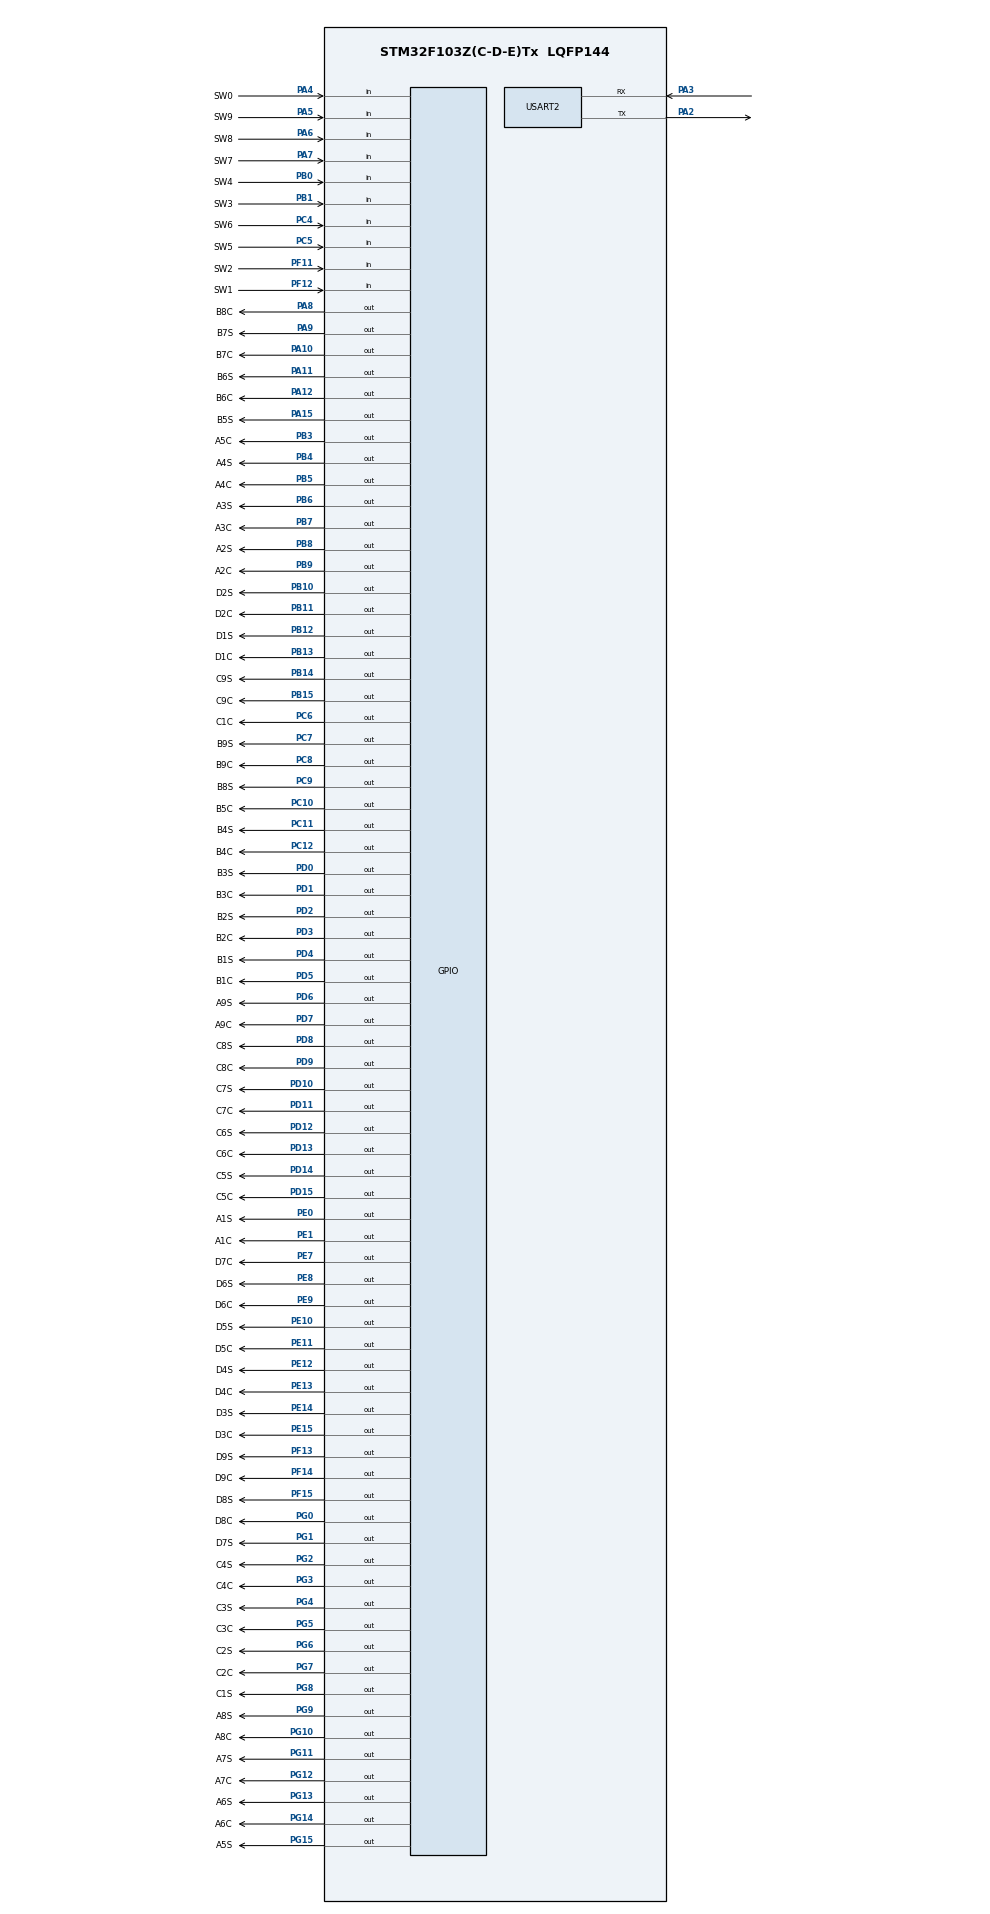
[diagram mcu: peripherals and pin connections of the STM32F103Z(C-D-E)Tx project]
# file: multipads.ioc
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Dma.Request0=USART2_RX
Dma.USART2_RX.0.Direction=DMA_PERIPH_TO_MEMORY
Dma.USART2_RX.0.Instance=DMA1_Channel6
Dma.USART2_RX.0.MemDataAlignment=DMA_MDATAALIGN_BYTE
Dma.USART2_RX.0.MemInc=DMA_MINC_ENABLE
Dma.USART2_RX.0.Mode=DMA_NORMAL
Dma.USART2_RX.0.PeriphDataAlignment=DMA_PDATAALIGN_BYTE
Dma.USART2_RX.0.PeriphInc=DMA_PINC_DISABLE
Dma.USART2_RX.0.Priority=DMA_PRIORITY_LOW
FREERTOS.Queues01=requestQueue,1,profile_t,0,Dynamic,NULL,NULL
FREERTOS.Tasks01=uxTask,0,1024,StartUxTask,As weak,NULL,Dynamic,NULL,NULL;profileTask,1,1024,StartProfileTask,As external,NULL,Dynamic,NULL,NULL
FREERTOS.configTOTAL_HEAP_SIZE=16384
FREERTOS.configUSE_NEWLIB_REENTRANT=1
Mcu.Family=STM32F1
Mcu.Name=STM32F103Z(C-D-E)Tx
Mcu.Package=LQFP144
NVIC.DMA1_Channel6_IRQn=true\:5\:0\:false\:false\:true\:true\:false\:true\:true
NVIC.PriorityGroup=NVIC_PRIORITYGROUP_4
NVIC.TIM1_UP_IRQn=true\:15\:0\:false\:false\:true\:false\:false\:true\:true
NVIC.TimeBase=TIM1_UP_IRQn
NVIC.TimeBaseIP=TIM1
OSC_IN.Mode=HSE-External-Oscillator
OSC_IN.Signal=RCC_OSC_IN
OSC_OUT.Mode=HSE-External-Oscillator
OSC_OUT.Signal=RCC_OSC_OUT
PA10.GPIO_Label=B7C
PA10.Signal=GPIO_Output
PA11.GPIO_Label=B6S
PA11.Signal=GPIO_Output
PA12.GPIO_Label=B6C
PA12.Signal=GPIO_Output
PA13.Mode=Serial_Wire
PA13.Signal=SYS_JTMS-SWDIO
PA14.Mode=Serial_Wire
PA14.Signal=SYS_JTCK-SWCLK
PA15.GPIO_Label=B5S
PA15.Signal=GPIO_Output
PA2.Mode=Asynchronous
PA2.Signal=USART2_TX
PA3.Mode=Asynchronous
PA3.Signal=USART2_RX
PA4.GPIO_Label=SW0
PA4.Signal=GPIO_Input
PA5.GPIO_Label=SW9
PA5.Signal=GPIO_Input
PA6.GPIO_Label=SW8
PA6.Signal=GPIO_Input
PA7.GPIO_Label=SW7
PA7.Signal=GPIO_Input
PA8.GPIO_Label=B8C
PA8.Signal=GPIO_Output
PA9.GPIO_Label=B7S
PA9.Signal=GPIO_Output
PB0.GPIO_Label=SW4
PB0.Signal=GPIO_Input
PB1.GPIO_Label=SW3
PB1.Signal=GPIO_Input
PB10.GPIO_Label=D2S
PB10.Signal=GPIO_Output
PB11.GPIO_Label=D2C
PB11.Signal=GPIO_Output
PB12.GPIO_Label=D1S
PB12.Signal=GPIO_Output
PB13.GPIO_Label=D1C
PB13.Signal=GPIO_Output
PB14.GPIO_Label=C9S
PB14.Signal=GPIO_Output
PB15.GPIO_Label=C9C
PB15.Signal=GPIO_Output
PB3.GPIO_Label=A5C
PB3.Signal=GPIO_Output
PB4.GPIO_Label=A4S
PB4.Signal=GPIO_Output
PB5.GPIO_Label=A4C
PB5.Signal=GPIO_Output
PB6.GPIO_Label=A3S
PB6.Signal=GPIO_Output
PB7.GPIO_Label=A3C
PB7.Signal=GPIO_Output
PB8.GPIO_Label=A2S
PB8.Signal=GPIO_Output
PB9.GPIO_Label=A2C
PB9.Signal=GPIO_Output
PC10.GPIO_Label=B5C
PC10.Signal=GPIO_Output
PC11.GPIO_Label=B4S
PC11.Signal=GPIO_Output
PC12.GPIO_Label=B4C
PC12.Signal=GPIO_Output
PC4.GPIO_Label=SW6
PC4.Signal=GPIO_Input
PC5.GPIO_Label=SW5
PC5.Signal=GPIO_Input
PC6.GPIO_Label=C1C
PC6.Signal=GPIO_Output
PC7.GPIO_Label=B9S
PC7.Signal=GPIO_Output
PC8.GPIO_Label=B9C
PC8.Signal=GPIO_Output
PC9.GPIO_Label=B8S
PC9.Signal=GPIO_Output
PD0.GPIO_Label=B3S
PD0.Signal=GPIO_Output
PD1.GPIO_Label=B3C
PD1.Signal=GPIO_Output
PD10.GPIO_Label=C7S
PD10.Signal=GPIO_Output
PD11.GPIO_Label=C7C
PD11.Signal=GPIO_Output
PD12.GPIO_Label=C6S
PD12.Signal=GPIO_Output
PD13.GPIO_Label=C6C
PD13.Signal=GPIO_Output
PD14.GPIO_Label=C5S
PD14.Signal=GPIO_Output
PD15.GPIO_Label=C5C
PD15.Signal=GPIO_Output
PD2.GPIO_Label=B2S
PD2.Signal=GPIO_Output
PD3.GPIO_Label=B2C
PD3.Signal=GPIO_Output
PD4.GPIO_Label=B1S
PD4.Signal=GPIO_Output
PD5.GPIO_Label=B1C
PD5.Signal=GPIO_Output
PD6.GPIO_Label=A9S
PD6.Signal=GPIO_Output
PD7.GPIO_Label=A9C
PD7.Signal=GPIO_Output
PD8.GPIO_Label=C8S
PD8.Signal=GPIO_Output
PD9.GPIO_Label=C8C
PD9.Signal=GPIO_Output
PE0.GPIO_Label=A1S
PE0.Signal=GPIO_Output
PE1.GPIO_Label=A1C
PE1.Signal=GPIO_Output
PE10.GPIO_Label=D5S
PE10.Signal=GPIO_Output
PE11.GPIO_Label=D5C
PE11.Signal=GPIO_Output
PE12.GPIO_Label=D4S
PE12.Signal=GPIO_Output
PE13.GPIO_Label=D4C
PE13.Signal=GPIO_Output
PE14.GPIO_Label=D3S
PE14.Signal=GPIO_Output
PE15.GPIO_Label=D3C
PE15.Signal=GPIO_Output
PE7.GPIO_Label=D7C
PE7.Signal=GPIO_Output
PE8.GPIO_Label=D6S
PE8.Signal=GPIO_Output
PE9.GPIO_Label=D6C
PE9.Signal=GPIO_Output
PF11.GPIO_Label=SW2
PF11.Signal=GPIO_Input
PF12.GPIO_Label=SW1
PF12.Signal=GPIO_Input
PF13.GPIO_Label=D9S
PF13.Signal=GPIO_Output
PF14.GPIO_Label=D9C
PF14.Signal=GPIO_Output
PF15.GPIO_Label=D8S
PF15.Signal=GPIO_Output
PG0.GPIO_Label=D8C
PG0.Signal=GPIO_Output
PG1.GPIO_Label=D7S
PG1.Signal=GPIO_Output
PG10.GPIO_Label=A8C
PG10.Signal=GPIO_Output
PG11.GPIO_Label=A7S
PG11.Signal=GPIO_Output
PG12.GPIO_Label=A7C
PG12.Signal=GPIO_Output
PG13.GPIO_Label=A6S
PG13.Signal=GPIO_Output
PG14.GPIO_Label=A6C
PG14.Signal=GPIO_Output
PG15.GPIO_Label=A5S
PG15.Signal=GPIO_Output
PG2.GPIO_Label=C4S
PG2.Signal=GPIO_Output
PG3.GPIO_Label=C4C
PG3.Signal=GPIO_Output
PG4.GPIO_Label=C3S
PG4.Signal=GPIO_Output
PG5.GPIO_Label=C3C
PG5.Signal=GPIO_Output
PG6.GPIO_Label=C2S
PG6.Signal=GPIO_Output
PG7.GPIO_Label=C2C
PG7.Signal=GPIO_Output
PG8.GPIO_Label=C1S
PG8.Signal=GPIO_Output
PG9.GPIO_Label=A8S
PG9.Signal=GPIO_Output
ProjectManager.HeapSize=0x200
ProjectManager.StackSize=0x400
ProjectManager.TargetToolchain=STM32CubeIDE
RCC.APB1Freq_Value=8000000
RCC.APB2Freq_Value=8000000
USART2.VirtualMode=VM_ASYNC
VP_CRC_VS_CRC.Mode=CRC_Activate
VP_FREERTOS_VS_CMSIS_V1.Mode=CMSIS_V1
VP_SYS_VS_tim1.Mode=TIM1
board=custom

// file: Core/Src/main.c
/* USER CODE BEGIN Header */
/**
  ******************************************************************************
  * @file           : main.c
  * @brief          : Main program body
  ******************************************************************************
  * @attention
  *
  * Copyright (c) 2023 STMicroelectronics.
  * All rights reserved.
  *
  * This software is licensed under terms that can be found in the LICENSE file
  * in the root directory of this software component.
  * If no LICENSE file comes with this software, it is provided AS-IS.
  *
  ******************************************************************************
  */

#include <string.h>
/* USER CODE END Header */
#include "main.h"
#include "cmsis_os.h"

/* USER CODE BEGIN Includes */
#include "command.h"
#include "profile.h"
/* USER CODE END Includes */

/* USER CODE BEGIN PTD */
typedef enum
{
	BTN_RELEASED = 0,
	BTN_DEBOUNCING,
	BTN_PRESSED,	// waiting for release
} BTN_StatusTypeDef;
/* USER CODE END PTD */

CRC_HandleTypeDef hcrc;

UART_HandleTypeDef huart2;
DMA_HandleTypeDef hdma_usart2_rx;

osThreadId uxTaskHandle;
osThreadId profileTaskHandle;
osMessageQId requestQueueHandle;
/* USER CODE BEGIN PV */

static BTN_StatusTypeDef btn_status = BTN_PRESSED;
int btn_index = -1;
int btn_count = 0;

/* USER CODE END PV */

void SystemClock_Config(void);
static void MX_GPIO_Init(void);
static void MX_DMA_Init(void);
static void MX_USART2_UART_Init(void);
static void MX_CRC_Init(void);
void StartUxTask(void const * argument);
extern void StartProfileTask(void const * argument);

/* USER CODE BEGIN 0 */
/*
 * Write char to uart in blocking mode
 */

// TODO remove this function
static void UART2_write(const char * str)
{
	int len = strlen(str);
	if (len == 0)
	{
		return;
	}

	HAL_UART_Transmit(&huart2, (const uint8_t *)str, len, HAL_MAX_DELAY);
}

void print_line(const char *str)
{
	UART2_write(str);
	UART2_write("\r\n");
}

/* USER CODE END 0 */

int main(void)
{

  /* MCU Configuration--------------------------------------------------------*/

  /* Reset of all peripherals, Initializes the Flash interface and the Systick. */
  HAL_Init();

  /* Configure the system clock */
  SystemClock_Config();

  /* Initialize all configured peripherals */
  MX_GPIO_Init();
  MX_DMA_Init();
  MX_USART2_UART_Init();
  MX_CRC_Init();

  /* Create the queue(s) */
  /* definition and creation of requestQueue */
  osMessageQDef(requestQueue, 1, profile_t);
  requestQueueHandle = osMessageCreate(osMessageQ(requestQueue), NULL);

  /* Create the thread(s) */
  /* definition and creation of uxTask */
  osThreadDef(uxTask, StartUxTask, osPriorityNormal, 0, 1024);
  uxTaskHandle = osThreadCreate(osThread(uxTask), NULL);

  /* definition and creation of profileTask */
  osThreadDef(profileTask, StartProfileTask, osPriorityAboveNormal, 0, 1024);
  profileTaskHandle = osThreadCreate(osThread(profileTask), NULL);

  /* Start scheduler */
  osKernelStart();

  /* We should never get here as control is now taken by the scheduler */

  /* Infinite loop */
  while (1)
  {

  }
}

void SystemClock_Config(void)
{
  RCC_OscInitTypeDef RCC_OscInitStruct = {0};
  RCC_ClkInitTypeDef RCC_ClkInitStruct = {0};

  /** Initializes the RCC Oscillators according to the specified parameters
  * in the RCC_OscInitTypeDef structure.
  */
  RCC_OscInitStruct.OscillatorType = RCC_OSCILLATORTYPE_HSI;
  RCC_OscInitStruct.HSIState = RCC_HSI_ON;
  RCC_OscInitStruct.HSICalibrationValue = RCC_HSICALIBRATION_DEFAULT;
  RCC_OscInitStruct.PLL.PLLState = RCC_PLL_NONE;
  if (HAL_RCC_OscConfig(&RCC_OscInitStruct) != HAL_OK)
  {
    Error_Handler();
  }

  /** Initializes the CPU, AHB and APB buses clocks
  */
  RCC_ClkInitStruct.ClockType = RCC_CLOCKTYPE_HCLK|RCC_CLOCKTYPE_SYSCLK
                              |RCC_CLOCKTYPE_PCLK1|RCC_CLOCKTYPE_PCLK2;
  RCC_ClkInitStruct.SYSCLKSource = RCC_SYSCLKSOURCE_HSI;
  RCC_ClkInitStruct.AHBCLKDivider = RCC_SYSCLK_DIV1;
  RCC_ClkInitStruct.APB1CLKDivider = RCC_HCLK_DIV1;
  RCC_ClkInitStruct.APB2CLKDivider = RCC_HCLK_DIV1;

  if (HAL_RCC_ClockConfig(&RCC_ClkInitStruct, FLASH_LATENCY_0) != HAL_OK)
  {
    Error_Handler();
  }
}

static void MX_CRC_Init(void)
{

  hcrc.Instance = CRC;
  if (HAL_CRC_Init(&hcrc) != HAL_OK)
  {
    Error_Handler();
  }

}

static void MX_USART2_UART_Init(void)
{

  huart2.Instance = USART2;
  huart2.Init.BaudRate = 115200;
  huart2.Init.WordLength = UART_WORDLENGTH_8B;
  huart2.Init.StopBits = UART_STOPBITS_1;
  huart2.Init.Parity = UART_PARITY_NONE;
  huart2.Init.Mode = UART_MODE_TX_RX;
  huart2.Init.HwFlowCtl = UART_HWCONTROL_NONE;
  huart2.Init.OverSampling = UART_OVERSAMPLING_16;
  if (HAL_UART_Init(&huart2) != HAL_OK)
  {
    Error_Handler();
  }

}

static void MX_DMA_Init(void)
{

  /* DMA controller clock enable */
  __HAL_RCC_DMA1_CLK_ENABLE();

  /* DMA interrupt init */
  /* DMA1_Channel6_IRQn interrupt configuration */
  HAL_NVIC_SetPriority(DMA1_Channel6_IRQn, 5, 0);
  HAL_NVIC_EnableIRQ(DMA1_Channel6_IRQn);

}

static void MX_GPIO_Init(void)
{
  GPIO_InitTypeDef GPIO_InitStruct = {0};

  /* GPIO Ports Clock Enable */
  __HAL_RCC_GPIOA_CLK_ENABLE();
  __HAL_RCC_GPIOC_CLK_ENABLE();
  __HAL_RCC_GPIOB_CLK_ENABLE();
  __HAL_RCC_GPIOF_CLK_ENABLE();
  __HAL_RCC_GPIOG_CLK_ENABLE();
  __HAL_RCC_GPIOE_CLK_ENABLE();
  __HAL_RCC_GPIOD_CLK_ENABLE();

  /*Configure GPIO pin Output Level */
  HAL_GPIO_WritePin(GPIOF, D9S_Pin|D9C_Pin|D8S_Pin, GPIO_PIN_RESET);

  /*Configure GPIO pin Output Level */
  HAL_GPIO_WritePin(GPIOG, D8C_Pin|D7S_Pin|C4S_Pin|C4C_Pin
                          |C3S_Pin|C3C_Pin|C2S_Pin|C2C_Pin
                          |C1S_Pin|A8S_Pin|A8C_Pin|A7S_Pin
                          |A7C_Pin|A6S_Pin|A6C_Pin|A5S_Pin, GPIO_PIN_RESET);

  /*Configure GPIO pin Output Level */
  HAL_GPIO_WritePin(GPIOE, D7C_Pin|D6S_Pin|D6C_Pin|D5S_Pin
                          |D5C_Pin|D4S_Pin|D4C_Pin|D3S_Pin
                          |D3C_Pin|A1S_Pin|A1C_Pin, GPIO_PIN_RESET);

  /*Configure GPIO pin Output Level */
  HAL_GPIO_WritePin(GPIOB, D2S_Pin|D2C_Pin|D1S_Pin|D1C_Pin
                          |C9S_Pin|C9C_Pin|A5C_Pin|A4S_Pin
                          |A4C_Pin|A3S_Pin|A3C_Pin|A2S_Pin
                          |A2C_Pin, GPIO_PIN_RESET);

  /*Configure GPIO pin Output Level */
  HAL_GPIO_WritePin(GPIOD, C8S_Pin|C8C_Pin|C7S_Pin|C7C_Pin
                          |C6S_Pin|C6C_Pin|C5S_Pin|C5C_Pin
                          |B3S_Pin|B3C_Pin|B2S_Pin|B2C_Pin
                          |B1S_Pin|B1C_Pin|A9S_Pin|A9C_Pin, GPIO_PIN_RESET);

  /*Configure GPIO pin Output Level */
  HAL_GPIO_WritePin(GPIOC, C1C_Pin|B9S_Pin|B9C_Pin|B8S_Pin
                          |B5C_Pin|B4S_Pin|B4C_Pin, GPIO_PIN_RESET);

  /*Configure GPIO pin Output Level */
  HAL_GPIO_WritePin(GPIOA, B8C_Pin|B7S_Pin|B7C_Pin|B6S_Pin
                          |B6C_Pin|B5S_Pin, GPIO_PIN_RESET);

  /*Configure GPIO pins : SW0_Pin SW9_Pin SW8_Pin SW7_Pin */
  GPIO_InitStruct.Pin = SW0_Pin|SW9_Pin|SW8_Pin|SW7_Pin;
  GPIO_InitStruct.Mode = GPIO_MODE_INPUT;
  GPIO_InitStruct.Pull = GPIO_NOPULL;
  HAL_GPIO_Init(GPIOA, &GPIO_InitStruct);

  /*Configure GPIO pins : SW6_Pin SW5_Pin */
  GPIO_InitStruct.Pin = SW6_Pin|SW5_Pin;
  GPIO_InitStruct.Mode = GPIO_MODE_INPUT;
  GPIO_InitStruct.Pull = GPIO_NOPULL;
  HAL_GPIO_Init(GPIOC, &GPIO_InitStruct);

  /*Configure GPIO pins : SW4_Pin SW3_Pin */
  GPIO_InitStruct.Pin = SW4_Pin|SW3_Pin;
  GPIO_InitStruct.Mode = GPIO_MODE_INPUT;
  GPIO_InitStruct.Pull = GPIO_NOPULL;
  HAL_GPIO_Init(GPIOB, &GPIO_InitStruct);

  /*Configure GPIO pins : SW2_Pin SW1_Pin */
  GPIO_InitStruct.Pin = SW2_Pin|SW1_Pin;
  GPIO_InitStruct.Mode = GPIO_MODE_INPUT;
  GPIO_InitStruct.Pull = GPIO_NOPULL;
  HAL_GPIO_Init(GPIOF, &GPIO_InitStruct);

  /*Configure GPIO pins : D9S_Pin D9C_Pin D8S_Pin */
  GPIO_InitStruct.Pin = D9S_Pin|D9C_Pin|D8S_Pin;
  GPIO_InitStruct.Mode = GPIO_MODE_OUTPUT_PP;
  GPIO_InitStruct.Pull = GPIO_NOPULL;
  GPIO_InitStruct.Speed = GPIO_SPEED_FREQ_LOW;
  HAL_GPIO_Init(GPIOF, &GPIO_InitStruct);

  /*Configure GPIO pins : D8C_Pin D7S_Pin C4S_Pin C4C_Pin
                           C3S_Pin C3C_Pin C2S_Pin C2C_Pin
                           C1S_Pin A8S_Pin A8C_Pin A7S_Pin
                           A7C_Pin A6S_Pin A6C_Pin A5S_Pin */
  GPIO_InitStruct.Pin = D8C_Pin|D7S_Pin|C4S_Pin|C4C_Pin
                          |C3S_Pin|C3C_Pin|C2S_Pin|C2C_Pin
                          |C1S_Pin|A8S_Pin|A8C_Pin|A7S_Pin
                          |A7C_Pin|A6S_Pin|A6C_Pin|A5S_Pin;
  GPIO_InitStruct.Mode = GPIO_MODE_OUTPUT_PP;
  GPIO_InitStruct.Pull = GPIO_NOPULL;
  GPIO_InitStruct.Speed = GPIO_SPEED_FREQ_LOW;
  HAL_GPIO_Init(GPIOG, &GPIO_InitStruct);

  /*Configure GPIO pins : D7C_Pin D6S_Pin D6C_Pin D5S_Pin
                           D5C_Pin D4S_Pin D4C_Pin D3S_Pin
                           D3C_Pin A1S_Pin A1C_Pin */
  GPIO_InitStruct.Pin = D7C_Pin|D6S_Pin|D6C_Pin|D5S_Pin
                          |D5C_Pin|D4S_Pin|D4C_Pin|D3S_Pin
                          |D3C_Pin|A1S_Pin|A1C_Pin;
  GPIO_InitStruct.Mode = GPIO_MODE_OUTPUT_PP;
  GPIO_InitStruct.Pull = GPIO_NOPULL;
  GPIO_InitStruct.Speed = GPIO_SPEED_FREQ_LOW;
  HAL_GPIO_Init(GPIOE, &GPIO_InitStruct);

  /*Configure GPIO pins : D2S_Pin D2C_Pin D1S_Pin D1C_Pin
                           C9S_Pin C9C_Pin A5C_Pin A4S_Pin
                           A4C_Pin A3S_Pin A3C_Pin A2S_Pin
                           A2C_Pin */
  GPIO_InitStruct.Pin = D2S_Pin|D2C_Pin|D1S_Pin|D1C_Pin
                          |C9S_Pin|C9C_Pin|A5C_Pin|A4S_Pin
                          |A4C_Pin|A3S_Pin|A3C_Pin|A2S_Pin
                          |A2C_Pin;
  GPIO_InitStruct.Mode = GPIO_MODE_OUTPUT_PP;
  GPIO_InitStruct.Pull = GPIO_NOPULL;
  GPIO_InitStruct.Speed = GPIO_SPEED_FREQ_LOW;
  HAL_GPIO_Init(GPIOB, &GPIO_InitStruct);

  /*Configure GPIO pins : C8S_Pin C8C_Pin C7S_Pin C7C_Pin
                           C6S_Pin C6C_Pin C5S_Pin C5C_Pin
                           B3S_Pin B3C_Pin B2S_Pin B2C_Pin
                           B1S_Pin B1C_Pin A9S_Pin A9C_Pin */
  GPIO_InitStruct.Pin = C8S_Pin|C8C_Pin|C7S_Pin|C7C_Pin
                          |C6S_Pin|C6C_Pin|C5S_Pin|C5C_Pin
                          |B3S_Pin|B3C_Pin|B2S_Pin|B2C_Pin
                          |B1S_Pin|B1C_Pin|A9S_Pin|A9C_Pin;
  GPIO_InitStruct.Mode = GPIO_MODE_OUTPUT_PP;
  GPIO_InitStruct.Pull = GPIO_NOPULL;
  GPIO_InitStruct.Speed = GPIO_SPEED_FREQ_LOW;
  HAL_GPIO_Init(GPIOD, &GPIO_InitStruct);

  /*Configure GPIO pins : C1C_Pin B9S_Pin B9C_Pin B8S_Pin
                           B5C_Pin B4S_Pin B4C_Pin */
  GPIO_InitStruct.Pin = C1C_Pin|B9S_Pin|B9C_Pin|B8S_Pin
                          |B5C_Pin|B4S_Pin|B4C_Pin;
  GPIO_InitStruct.Mode = GPIO_MODE_OUTPUT_PP;
  GPIO_InitStruct.Pull = GPIO_NOPULL;
  GPIO_InitStruct.Speed = GPIO_SPEED_FREQ_LOW;
  HAL_GPIO_Init(GPIOC, &GPIO_InitStruct);

  /*Configure GPIO pins : B8C_Pin B7S_Pin B7C_Pin B6S_Pin
                           B6C_Pin B5S_Pin */
  GPIO_InitStruct.Pin = B8C_Pin|B7S_Pin|B7C_Pin|B6S_Pin
                          |B6C_Pin|B5S_Pin;
  GPIO_InitStruct.Mode = GPIO_MODE_OUTPUT_PP;
  GPIO_InitStruct.Pull = GPIO_NOPULL;
  GPIO_InitStruct.Speed = GPIO_SPEED_FREQ_LOW;
  HAL_GPIO_Init(GPIOA, &GPIO_InitStruct);

}

/* USER CODE BEGIN 4 */
static uint32_t BTN_KeyScan()
{
	uint32_t idr, code = 0;

	idr = GPIOA->IDR;
	if (!(idr & SW0_Pin))	// active low!
	{
		code |= (1UL << 0);
	}

	if (!(idr & SW7_Pin))
	{
		code |= (1UL << 7);
	}

	if (!(idr & SW8_Pin))
	{
		code |= (1UL << 8);
	}

	if (!(idr & SW9_Pin))
	{
		code |= (1UL << 9);
	}

	idr = GPIOB->IDR;
	if (!(idr & SW3_Pin))
	{
		code |= (1UL << 3);
	}

	if (!(idr & SW4_Pin))
	{
		code |= (1UL << 4);
	}

	idr = GPIOC->IDR;
	if (!(idr & SW5_Pin))
	{
		code |= (1UL << 5);
	}
	if (!(idr & SW6_Pin))
	{
		code |= (1UL << 6);
	}

	idr = GPIOF->IDR;
	if (!(idr & SW1_Pin))
	{
		code |= (1UL << 1);
	}
	if (!(idr & SW2_Pin))
	{
		code |= (1UL << 2);
	}

	return code;
}

/* return key index if single key pressed in given key code.
 * return -1 if no key is pressed.
 * return -2 if multiple keys are pressed.
 * this is a level detector.
 */
static int BTN_SingleKeyPress(uint32_t code)
{
	int i, index, count = 0;
	for (i = 0; i < 32; i++)
	{
		if (code & (1UL << i))
		{
			index = i;
			count++;
		}
	}

	if (count == 0)
	{
		return -1;
	}
	else if (count == 1)
	{
		return index;
	}
	else
	{
		return -2;
	}
}

/* return key index if single key pressed down.
 * return -1 if no key down detected (may or may not be pressed)
 * this is an edge detector.
 */
static int BTN_SingleKeyDown()
{
	uint32_t code = BTN_KeyScan();
	int index = BTN_SingleKeyPress(code);
	switch (btn_status)
	{
	case BTN_RELEASED:
		if (index < 0)
		{
			// do nothing
		}
		else
		{
			btn_status = BTN_DEBOUNCING;
			btn_index = index;
			btn_count = 1;
		}
		break;
	case BTN_DEBOUNCING:
		if (index == -2) // multiple keys pressed?
		{
			btn_status = BTN_PRESSED;
			btn_index = -1;
			btn_count = 0;
		}
		else if (index == -1) // no keys pressed
		{
			btn_status = BTN_RELEASED;
			btn_index = -1;
			btn_count = 0;
		}
		else if (index == btn_index)
		{
			btn_count++;
			if (btn_count > 3)
			{
				btn_status = BTN_PRESSED;
				btn_index = -1;
				btn_count = 0;
				return index;
			}
			// otherwise, status and index unchanged
		}
		else // another key pressed in debouncing?
		{
			btn_status = BTN_PRESSED;
			btn_index = index;
			btn_count = 1;
		}
		break;
	case BTN_PRESSED:	// no change in btn_index and btn_count in this state
		if (index == -1)
		{
			btn_status = BTN_RELEASED;
			// btn_index = -1;
			// btn_count = 0;
		}
		break;
	}
	return -1;
}

int detect_single_keydown(void)
{
	return BTN_SingleKeyDown();
}

/* USER CODE END 4 */

__weak void StartUxTask(void const * argument)
{
}

void HAL_TIM_PeriodElapsedCallback(TIM_HandleTypeDef *htim)
{
  if (htim->Instance == TIM1)
  {
    HAL_IncTick();
  }
}

void Error_Handler(void)
{
  __disable_irq();
  while (1)
  {
  }
}
